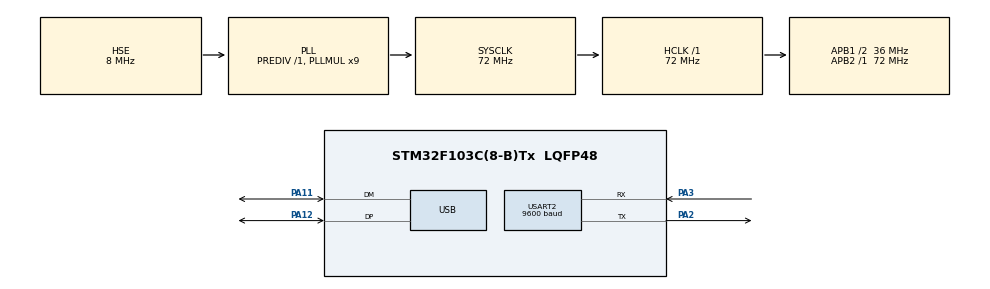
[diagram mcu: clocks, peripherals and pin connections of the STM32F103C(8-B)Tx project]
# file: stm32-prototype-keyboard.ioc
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Mcu.Family=STM32F1
Mcu.Name=STM32F103C(8-B)Tx
Mcu.Package=LQFP48
NVIC.PriorityGroup=NVIC_PRIORITYGROUP_4
NVIC.USART2_IRQn=true\:0\:0\:false\:false\:true\:true\:true\:true
NVIC.USB_LP_CAN1_RX0_IRQn=true\:0\:0\:false\:false\:true\:false\:true\:true
PA11.Mode=Device
PA11.Signal=USB_DM
PA12.Mode=Device
PA12.Signal=USB_DP
PA13.Mode=Serial_Wire
PA13.Signal=SYS_JTMS-SWDIO
PA14.Mode=Serial_Wire
PA14.Signal=SYS_JTCK-SWCLK
PA2.Mode=Asynchronous
PA2.Signal=USART2_TX
PA3.Mode=Asynchronous
PA3.Signal=USART2_RX
PD0-OSC_IN.Mode=HSE-External-Oscillator
PD0-OSC_IN.Signal=RCC_OSC_IN
PD1-OSC_OUT.Mode=HSE-External-Oscillator
PD1-OSC_OUT.Signal=RCC_OSC_OUT
ProjectManager.HeapSize=0x200
ProjectManager.StackSize=0x400
ProjectManager.TargetToolchain=Makefile
RCC.AHBFreq_Value=72000000
RCC.APB1CLKDivider=RCC_HCLK_DIV2
RCC.APB1Freq_Value=36000000
RCC.APB1TimFreq_Value=72000000
RCC.APB2Freq_Value=72000000
RCC.APB2TimFreq_Value=72000000
RCC.HCLKFreq_Value=72000000
RCC.PLLMUL=RCC_PLL_MUL9
RCC.SYSCLKFreq_VALUE=72000000
RCC.SYSCLKSource=RCC_SYSCLKSOURCE_PLLCLK
RCC.USBFreq_Value=48000000
RCC.USBPrescaler=RCC_USBCLKSOURCE_PLL_DIV1_5
USART2.BaudRate=9600
USART2.Mode=MODE_RX
USART2.VirtualMode=VM_ASYNC
USB_DEVICE.CLASS_NAME_FS=HID
USB_DEVICE.PRODUCT_STRING_HID_FS=stm32-prototype-keyboard
USB_DEVICE.VirtualMode=Hid
USB_DEVICE.VirtualModeFS=Hid_FS
VP_USB_DEVICE_VS_USB_DEVICE_HID_FS.Mode=HID_FS
board=custom

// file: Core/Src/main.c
/* USER CODE BEGIN Header */
/**
 ******************************************************************************
 * @file           : main.c
 * @brief          : Main program body
 ******************************************************************************
 * @attention
 *
 * Copyright (c) 2022 STMicroelectronics.
 * All rights reserved.
 *
 * This software is licensed under terms that can be found in the LICENSE file
 * in the root directory of this software component.
 * If no LICENSE file comes with this software, it is provided AS-IS.
 *
 ******************************************************************************
 */
/* USER CODE END Header */
#include "main.h"
#include "usb_device.h"
#include "usbd_hid.h"

/* USER CODE BEGIN Includes */
#include "keyboard.h"
/* USER CODE END Includes */

UART_HandleTypeDef huart2;

/* USER CODE BEGIN PV */
extern USBD_HandleTypeDef hUsbDeviceFS;
char msg_buff[100] = {0};
/* USER CODE END PV */

void SystemClock_Config(void);
static void MX_GPIO_Init(void);
static void MX_USART2_UART_Init(void);

int main(void) {

  /* MCU Configuration--------------------------------------------------------*/

  /* Reset of all peripherals, Initializes the Flash interface and the Systick.
   */
  HAL_Init();

  /* Configure the system clock */
  SystemClock_Config();

  /* Initialize all configured peripherals */
  MX_GPIO_Init();
  MX_USART2_UART_Init();
  MX_USB_DEVICE_Init();
  /* USER CODE BEGIN 2 */
  sprintf(msg_buff, "Wuque Studio\n");
  /* USER CODE END 2 */

  /* Infinite loop */
  while (1) {

    /* USER CODE BEGIN 3 */
    keyboard_print(msg_buff, strlen(msg_buff));
    HAL_Delay(1000);
  }
  /* USER CODE END 3 */
}

void SystemClock_Config(void) {
  RCC_OscInitTypeDef RCC_OscInitStruct = {0};
  RCC_ClkInitTypeDef RCC_ClkInitStruct = {0};
  RCC_PeriphCLKInitTypeDef PeriphClkInit = {0};

  /** Initializes the RCC Oscillators according to the specified parameters
   * in the RCC_OscInitTypeDef structure.
   */
  RCC_OscInitStruct.OscillatorType = RCC_OSCILLATORTYPE_HSE;
  RCC_OscInitStruct.HSEState = RCC_HSE_ON;
  RCC_OscInitStruct.HSEPredivValue = RCC_HSE_PREDIV_DIV1;
  RCC_OscInitStruct.HSIState = RCC_HSI_ON;
  RCC_OscInitStruct.PLL.PLLState = RCC_PLL_ON;
  RCC_OscInitStruct.PLL.PLLSource = RCC_PLLSOURCE_HSE;
  RCC_OscInitStruct.PLL.PLLMUL = RCC_PLL_MUL9;
  if (HAL_RCC_OscConfig(&RCC_OscInitStruct) != HAL_OK) {
    Error_Handler();
  }

  /** Initializes the CPU, AHB and APB buses clocks
   */
  RCC_ClkInitStruct.ClockType = RCC_CLOCKTYPE_HCLK | RCC_CLOCKTYPE_SYSCLK |
                                RCC_CLOCKTYPE_PCLK1 | RCC_CLOCKTYPE_PCLK2;
  RCC_ClkInitStruct.SYSCLKSource = RCC_SYSCLKSOURCE_PLLCLK;
  RCC_ClkInitStruct.AHBCLKDivider = RCC_SYSCLK_DIV1;
  RCC_ClkInitStruct.APB1CLKDivider = RCC_HCLK_DIV2;
  RCC_ClkInitStruct.APB2CLKDivider = RCC_HCLK_DIV1;

  if (HAL_RCC_ClockConfig(&RCC_ClkInitStruct, FLASH_LATENCY_2) != HAL_OK) {
    Error_Handler();
  }
  PeriphClkInit.PeriphClockSelection = RCC_PERIPHCLK_USB;
  PeriphClkInit.UsbClockSelection = RCC_USBCLKSOURCE_PLL_DIV1_5;
  if (HAL_RCCEx_PeriphCLKConfig(&PeriphClkInit) != HAL_OK) {
    Error_Handler();
  }
}

static void MX_USART2_UART_Init(void) {

  huart2.Instance = USART2;
  huart2.Init.BaudRate = 9600;
  huart2.Init.WordLength = UART_WORDLENGTH_8B;
  huart2.Init.StopBits = UART_STOPBITS_1;
  huart2.Init.Parity = UART_PARITY_NONE;
  huart2.Init.Mode = UART_MODE_RX;
  huart2.Init.HwFlowCtl = UART_HWCONTROL_NONE;
  huart2.Init.OverSampling = UART_OVERSAMPLING_16;
  if (HAL_UART_Init(&huart2) != HAL_OK) {
    Error_Handler();
  }
}

static void MX_GPIO_Init(void) {

  /* GPIO Ports Clock Enable */
  __HAL_RCC_GPIOD_CLK_ENABLE();
  __HAL_RCC_GPIOA_CLK_ENABLE();
}

void Error_Handler(void) {
  __disable_irq();
  while (1) {
  }
}

#ifdef USE_FULL_ASSERT
/**
 * @brief  Reports the name of the source file and the source line number
 *         where the assert_param error has occurred.
 * @param  file: pointer to the source file name
 * @param  line: assert_param error line source number
 * @retval None
 */
void assert_failed(uint8_t *file, uint32_t line) {
  /* USER CODE BEGIN 6 */
  /* User can add his own implementation to report the file name and line
     number, ex: printf("Wrong parameters value: file %s on line %d\r\n", file,
     line) */
  /* USER CODE END 6 */
}
#endif /* USE_FULL_ASSERT */
